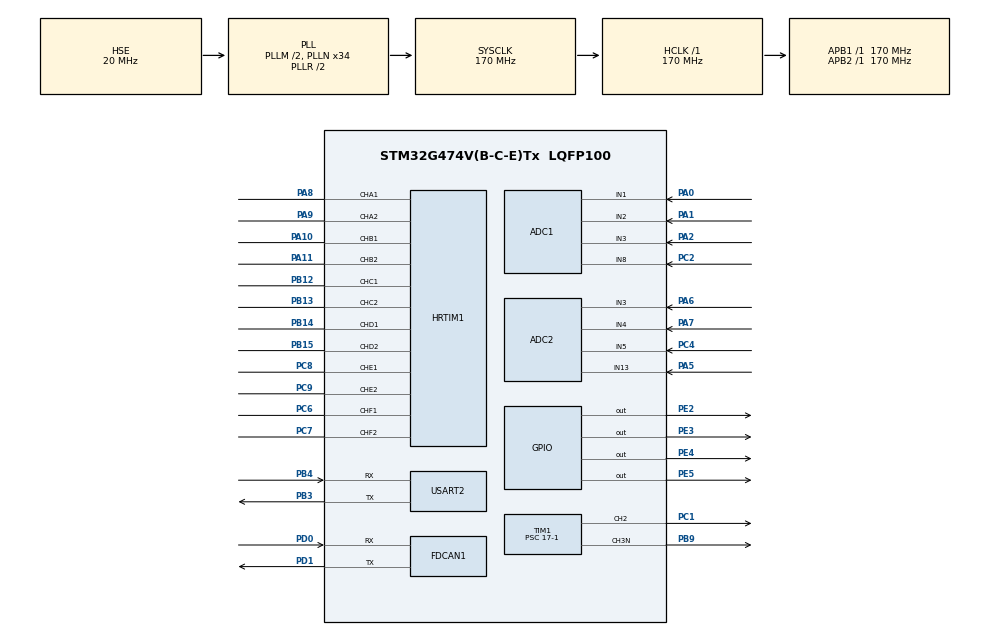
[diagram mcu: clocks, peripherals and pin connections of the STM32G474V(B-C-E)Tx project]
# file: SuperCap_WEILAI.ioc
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ADC1.Channel-22\#ChannelRegularConversion=ADC_CHANNEL_2
ADC1.Channel-23\#ChannelRegularConversion=ADC_CHANNEL_8
ADC1.ClockPrescaler=ADC_CLOCK_ASYNC_DIV8
ADC1.ContinuousConvMode=DISABLE
ADC1.DMAContinuousRequests=ENABLE
ADC1.DiscontinuousConvMode=DISABLE
ADC1.EOCSelection=ADC_EOC_SEQ_CONV
ADC1.EnableInjectedConversion=ENABLE
ADC1.EnableRegularConversion=ENABLE
ADC1.ExternalTrigConv=ADC_EXTERNALTRIG_HRTIM_TRG1
ADC1.ExternalTrigInjecConv=ADC_EXTERNALTRIGINJEC_HRTIM_TRG4
ADC1.GainCompensation=0
ADC1.InjNumberOfConversion=2
ADC1.InjectedChannel-20\#ChannelInjectedConversion=ADC_CHANNEL_1
ADC1.InjectedChannel-21\#ChannelInjectedConversion=ADC_CHANNEL_3
ADC1.InjectedOffsetNumber-20\#ChannelInjectedConversion=ADC_OFFSET_NONE
ADC1.InjectedOffsetNumber-21\#ChannelInjectedConversion=ADC_OFFSET_NONE
ADC1.InjectedRank-20\#ChannelInjectedConversion=1
ADC1.InjectedRank-21\#ChannelInjectedConversion=2
ADC1.InjectedSamplingTime-20\#ChannelInjectedConversion=ADC_SAMPLETIME_6CYCLES_5
ADC1.InjectedSamplingTime-21\#ChannelInjectedConversion=ADC_SAMPLETIME_6CYCLES_5
ADC1.Mode=ADC_MODE_INDEPENDENT
ADC1.NbrOfConversion=2
ADC1.NbrOfConversionFlag=1
ADC1.OffsetNumber-22\#ChannelRegularConversion=ADC_OFFSET_NONE
ADC1.OffsetNumber-23\#ChannelRegularConversion=ADC_OFFSET_NONE
ADC1.Overrun=ADC_OVR_DATA_OVERWRITTEN
ADC1.Rank-22\#ChannelRegularConversion=1
ADC1.Rank-23\#ChannelRegularConversion=2
ADC1.Rank1_Channel=ADC_CHANNEL_1
ADC1.Rank2_Channel=ADC_CHANNEL_3
ADC1.Rank3_Channel=ADC_CHANNEL_1
ADC1.Rank4_Channel=ADC_CHANNEL_1
ADC1.SamplingTime-22\#ChannelRegularConversion=ADC_SAMPLETIME_6CYCLES_5
ADC1.SamplingTime-23\#ChannelRegularConversion=ADC_SAMPLETIME_6CYCLES_5
ADC1.injectedQueueMode=DISABLE
ADC1.master=1
ADC2.Channel-0\#ChannelRegularConversion=ADC_CHANNEL_3
ADC2.Channel-1\#ChannelRegularConversion=ADC_CHANNEL_4
ADC2.Channel-2\#ChannelRegularConversion=ADC_CHANNEL_5
ADC2.Channel-3\#ChannelRegularConversion=ADC_CHANNEL_13
ADC2.ClockPrescaler=ADC_CLOCK_ASYNC_DIV8
ADC2.ContinuousConvMode=DISABLE
ADC2.DMAContinuousRequests=ENABLE
ADC2.ExternalTrigConv=ADC_EXTERNALTRIG_HRTIM_TRG10
ADC2.NbrOfConversion=4
ADC2.NbrOfConversionFlag=1
ADC2.OffsetNumber-0\#ChannelRegularConversion=ADC_OFFSET_NONE
ADC2.OffsetNumber-1\#ChannelRegularConversion=ADC_OFFSET_NONE
ADC2.OffsetNumber-2\#ChannelRegularConversion=ADC_OFFSET_NONE
ADC2.OffsetNumber-3\#ChannelRegularConversion=ADC_OFFSET_NONE
ADC2.Overrun=ADC_OVR_DATA_OVERWRITTEN
ADC2.Rank-0\#ChannelRegularConversion=1
ADC2.Rank-1\#ChannelRegularConversion=2
ADC2.Rank-2\#ChannelRegularConversion=3
ADC2.Rank-3\#ChannelRegularConversion=4
ADC2.SamplingTime-0\#ChannelRegularConversion=ADC_SAMPLETIME_6CYCLES_5
ADC2.SamplingTime-1\#ChannelRegularConversion=ADC_SAMPLETIME_6CYCLES_5
ADC2.SamplingTime-2\#ChannelRegularConversion=ADC_SAMPLETIME_6CYCLES_5
ADC2.SamplingTime-3\#ChannelRegularConversion=ADC_SAMPLETIME_6CYCLES_5
Dma.ADC1.1.Direction=DMA_PERIPH_TO_MEMORY
Dma.ADC1.1.EventEnable=DISABLE
Dma.ADC1.1.Instance=DMA1_Channel1
Dma.ADC1.1.MemDataAlignment=DMA_MDATAALIGN_WORD
Dma.ADC1.1.MemInc=DMA_MINC_ENABLE
Dma.ADC1.1.Mode=DMA_CIRCULAR
Dma.ADC1.1.PeriphDataAlignment=DMA_PDATAALIGN_HALFWORD
Dma.ADC1.1.PeriphInc=DMA_PINC_DISABLE
Dma.ADC1.1.Polarity=HAL_DMAMUX_REQ_GEN_RISING
Dma.ADC1.1.Priority=DMA_PRIORITY_VERY_HIGH
Dma.ADC1.1.RequestNumber=1
Dma.ADC1.1.SignalID=NONE
Dma.ADC1.1.SyncEnable=DISABLE
Dma.ADC1.1.SyncPolarity=HAL_DMAMUX_SYNC_NO_EVENT
Dma.ADC1.1.SyncRequestNumber=1
Dma.ADC1.1.SyncSignalID=NONE
Dma.ADC2.0.Direction=DMA_PERIPH_TO_MEMORY
Dma.ADC2.0.EventEnable=DISABLE
Dma.ADC2.0.Instance=DMA1_Channel2
Dma.ADC2.0.MemDataAlignment=DMA_MDATAALIGN_WORD
Dma.ADC2.0.MemInc=DMA_MINC_ENABLE
Dma.ADC2.0.Mode=DMA_CIRCULAR
Dma.ADC2.0.PeriphDataAlignment=DMA_PDATAALIGN_HALFWORD
Dma.ADC2.0.PeriphInc=DMA_PINC_DISABLE
Dma.ADC2.0.Polarity=HAL_DMAMUX_REQ_GEN_RISING
Dma.ADC2.0.Priority=DMA_PRIORITY_VERY_HIGH
Dma.ADC2.0.RequestNumber=1
Dma.ADC2.0.SignalID=NONE
Dma.ADC2.0.SyncEnable=DISABLE
Dma.ADC2.0.SyncPolarity=HAL_DMAMUX_SYNC_NO_EVENT
Dma.ADC2.0.SyncRequestNumber=1
Dma.ADC2.0.SyncSignalID=NONE
Dma.Request0=ADC2
Dma.Request1=ADC1
FDCAN1.CalculateBaudRateNominal=1000000
FDCAN1.CalculateTimeBitNominal=1000
FDCAN1.CalculateTimeQuantumNominal=100.0
FDCAN1.NominalPrescaler=17
FDCAN1.NominalTimeSeg1=7
FDCAN1.NominalTimeSeg2=2
FDCAN1.StdFiltersNbr=1
HRTIM1.ADCTrigger1_Source1=HRTIM_ADCTRIGGEREVENT13_TIMERF_CMP2
HRTIM1.ADCTrigger4_Source1=HRTIM_ADCTRIGGEREVENT24_TIMERB_CMP2
HRTIM1.ADCTrigger_Id1=HRTIM_ADCTRIGGER_1
HRTIM1.ADCTrigger_Id10=HRTIM_ADCTRIGGER_10
HRTIM1.ADCTrigger_Id2=__NULL
HRTIM1.ADCTrigger_Id3=__NULL
HRTIM1.ADCTrigger_Id4=HRTIM_ADCTRIGGER_4
HRTIM1.ADCTrigger_Id5=__NULL
HRTIM1.ADCTrigger_Id9=__NULL
HRTIM1.BurstMode-Output_TA1TA2=HRTIM_TIMERBURSTMODE_MAINTAINCLOCK
HRTIM1.CompareUnit1-MasterTimer=HRTIM_COMPAREUNIT_1
HRTIM1.CompareUnit1-Output_TA1TA2=HRTIM_COMPAREUNIT_1
HRTIM1.CompareUnit1-Output_TB1TB2=HRTIM_COMPAREUNIT_1
HRTIM1.CompareUnit1-Output_TC1TC2=HRTIM_COMPAREUNIT_1
HRTIM1.CompareUnit1-Output_TD1TD2=HRTIM_COMPAREUNIT_1
HRTIM1.CompareUnit1-Output_TE1TE2=HRTIM_COMPAREUNIT_1
HRTIM1.CompareUnit1-Output_TF1TF2=HRTIM_COMPAREUNIT_1
HRTIM1.CompareUnit2-MasterTimer=HRTIM_COMPAREUNIT_2
HRTIM1.CompareUnit2-Output_TA1TA2=HRTIM_COMPAREUNIT_2
HRTIM1.CompareUnit2-Output_TB1TB2=HRTIM_COMPAREUNIT_2
HRTIM1.CompareUnit2-Output_TC1TC2=HRTIM_COMPAREUNIT_2
HRTIM1.CompareUnit2-Output_TD1TD2=HRTIM_COMPAREUNIT_2
HRTIM1.CompareUnit2-Output_TE1TE2=HRTIM_COMPAREUNIT_2
HRTIM1.CompareUnit2-Output_TF1TF2=HRTIM_COMPAREUNIT_2
HRTIM1.CompareUnit3-Output_TA1TA2=HRTIM_COMPAREUNIT_3
HRTIM1.CompareUnit3-Output_TB1TB2=HRTIM_COMPAREUNIT_3
HRTIM1.CompareUnit3-Output_TC1TC2=HRTIM_COMPAREUNIT_3
HRTIM1.CompareUnit3-Output_TD1TD2=HRTIM_COMPAREUNIT_3
HRTIM1.CompareUnit3-Output_TE1TE2=HRTIM_COMPAREUNIT_3
HRTIM1.CompareUnit3-Output_TF1TF2=HRTIM_COMPAREUNIT_3
HRTIM1.CompareUnit4-Output_TA1TA2=__NULL
HRTIM1.CompareValue1-MasterTimer=8000
HRTIM1.CompareValue1-Output_TA1TA2=0xFFDF
HRTIM1.CompareValue1-Output_TB1TB2=0xFFDF
HRTIM1.CompareValue1-Output_TC1TC2=0xFFDF
HRTIM1.CompareValue1-Output_TD1TD2=0xFFDF
HRTIM1.CompareValue1-Output_TE1TE2=0xFFDF
HRTIM1.CompareValue1-Output_TF1TF2=0xFFDF
HRTIM1.CompareValue2-MasterTimer=16000
HRTIM1.CompareValue2-Output_TA1TA2=12000
HRTIM1.CompareValue2-Output_TB1TB2=12000
HRTIM1.CompareValue2-Output_TC1TC2=12000
HRTIM1.CompareValue2-Output_TD1TD2=12000
HRTIM1.CompareValue2-Output_TE1TE2=12000
HRTIM1.CompareValue2-Output_TF1TF2=12000
HRTIM1.CompareValue3-Output_TE1TE2=0xFFDF
HRTIM1.DeadTimeInsertion-Output_TA1TA2=HRTIM_TIMDEADTIMEINSERTION_ENABLED
HRTIM1.DeadTimeInsertion-Output_TB1TB2=HRTIM_TIMDEADTIMEINSERTION_ENABLED
HRTIM1.DeadTimeInsertion-Output_TC1TC2=HRTIM_TIMDEADTIMEINSERTION_ENABLED
HRTIM1.DeadTimeInsertion-Output_TD1TD2=HRTIM_TIMDEADTIMEINSERTION_ENABLED
HRTIM1.DeadTimeInsertion-Output_TE1TE2=HRTIM_TIMDEADTIMEINSERTION_ENABLED
HRTIM1.DeadTimeInsertion-Output_TF1TF2=HRTIM_TIMDEADTIMEINSERTION_ENABLED
HRTIM1.FallingValue-Output_TA1TA2=55
HRTIM1.FallingValue-Output_TB1TB2=55
HRTIM1.FallingValue-Output_TC1TC2=55
HRTIM1.FallingValue-Output_TD1TD2=55
HRTIM1.FallingValue-Output_TE1TE2=55
HRTIM1.FallingValue-Output_TF1TF2=55
HRTIM1.FaultLevel1-Output_TA1TA2=HRTIM_OUTPUTFAULTLEVEL_INACTIVE
HRTIM1.FaultLevel1-Output_TC1TC2=HRTIM_OUTPUTFAULTLEVEL_INACTIVE
HRTIM1.FaultLevel1-Output_TD1TD2=HRTIM_OUTPUTFAULTLEVEL_INACTIVE
HRTIM1.FaultLevel1-Output_TE1TE2=HRTIM_OUTPUTFAULTLEVEL_INACTIVE
HRTIM1.FaultLevel1-Output_TF1TF2=HRTIM_OUTPUTFAULTLEVEL_INACTIVE
HRTIM1.FaultLevel2-Output_TA1TA2=HRTIM_OUTPUTFAULTLEVEL_INACTIVE
HRTIM1.FaultLevel2-Output_TC1TC2=HRTIM_OUTPUTFAULTLEVEL_INACTIVE
HRTIM1.FaultLevel2-Output_TD1TD2=HRTIM_OUTPUTFAULTLEVEL_INACTIVE
HRTIM1.FaultLevel2-Output_TE1TE2=HRTIM_OUTPUTFAULTLEVEL_INACTIVE
HRTIM1.FaultLevel2-Output_TF1TF2=HRTIM_OUTPUTFAULTLEVEL_INACTIVE
HRTIM1.FaultLock-Output_TA1TA2=HRTIM_TIMFAULTLOCK_READWRITE
HRTIM1.InterruptRequests1_Master=HRTIM_MASTER_IT_MREP
HRTIM1.NumberADCTriggerSource1=1
HRTIM1.NumberADCTriggerSource4=1
HRTIM1.NumberFaultEnable-Output_TA1TA2=0
HRTIM1.NumberInterruptRequests_Master-MasterTimer=1
HRTIM1.NumberResetSource1-Output_TA1TA2=1
HRTIM1.NumberResetSource1-Output_TB1TB2=1
HRTIM1.NumberResetSource1-Output_TC1TC2=1
HRTIM1.NumberResetSource1-Output_TD1TD2=1
HRTIM1.NumberResetSource1-Output_TE1TE2=1
HRTIM1.NumberResetSource1-Output_TF1TF2=1
HRTIM1.NumberResetSource2_TB=0
HRTIM1.NumberResetTrigger-Output_TA1TA2=1
HRTIM1.NumberResetTrigger-Output_TB1TB2=1
HRTIM1.NumberResetTrigger-Output_TC1TC2=1
HRTIM1.NumberResetTrigger-Output_TD1TD2=1
HRTIM1.NumberResetTrigger-Output_TE1TE2=1
HRTIM1.NumberResetTrigger-Output_TF1TF2=1
HRTIM1.NumberSetSource1-Output_TA1TA2=1
HRTIM1.NumberSetSource1-Output_TB1TB2=1
HRTIM1.NumberSetSource1-Output_TC1TC2=1
HRTIM1.NumberSetSource1-Output_TD1TD2=1
HRTIM1.NumberSetSource1-Output_TE1TE2=1
HRTIM1.NumberSetSource1-Output_TF1TF2=1
HRTIM1.NumberSetSource2_TA=0
HRTIM1.NumberUpdateTrigger-Output_TA1TA2=0
HRTIM1.NumberUpdateTrigger-Output_TF1TF2=0
HRTIM1.ORingUpdateSource_ADCTrigger1=HRTIM_ADCTRIGGERUPDATE_TIMER_F
HRTIM1.ORingUpdateSource_ADCTrigger10=HRTIM_ADCTRIGGERUPDATE_TIMER_C
HRTIM1.ORingUpdateSource_ADCTrigger4=HRTIM_ADCTRIGGERUPDATE_TIMER_B
HRTIM1.Periode_MASTER=24000
HRTIM1.Periode_TA=24000
HRTIM1.Periode_TB=24000
HRTIM1.Periode_TC=24000
HRTIM1.Periode_TD=24000
HRTIM1.Periode_TE=24000
HRTIM1.Periode_TF=24000
HRTIM1.PreloadEnable-MasterTimer=HRTIM_PRELOAD_ENABLED
HRTIM1.PreloadEnable-Output_TA1TA2=HRTIM_PRELOAD_ENABLED
HRTIM1.PreloadEnable-Output_TB1TB2=HRTIM_PRELOAD_ENABLED
HRTIM1.PreloadEnable-Output_TC1TC2=HRTIM_PRELOAD_ENABLED
HRTIM1.PreloadEnable-Output_TD1TD2=HRTIM_PRELOAD_ENABLED
HRTIM1.PreloadEnable-Output_TE1TE2=HRTIM_PRELOAD_ENABLED
HRTIM1.PreloadEnable-Output_TF1TF2=HRTIM_PRELOAD_ENABLED
HRTIM1.PrescalerDead-Output_TA1TA2=HRTIM_TIMDEADTIME_PRESCALERRATIO_DIV8
HRTIM1.PrescalerDead-Output_TB1TB2=HRTIM_TIMDEADTIME_PRESCALERRATIO_DIV8
HRTIM1.PrescalerDead-Output_TC1TC2=HRTIM_TIMDEADTIME_PRESCALERRATIO_DIV8
HRTIM1.PrescalerDead-Output_TD1TD2=HRTIM_TIMDEADTIME_PRESCALERRATIO_DIV8
HRTIM1.PrescalerDead-Output_TE1TE2=HRTIM_TIMDEADTIME_PRESCALERRATIO_DIV8
HRTIM1.PrescalerDead-Output_TF1TF2=HRTIM_TIMDEADTIME_PRESCALERRATIO_DIV8
HRTIM1.PrescalerRatio_MASTER=HRTIM_PRESCALERRATIO_MUL32
HRTIM1.RepetitionCounter-MasterTimer=8-1
HRTIM1.RepetitionUpdate-MasterTimer=HRTIM_UPDATEONREPETITION_ENABLED
HRTIM1.RepetitionUpdate-Output_TA1TA2=HRTIM_UPDATEONREPETITION_ENABLED
HRTIM1.RepetitionUpdate-Output_TB1TB2=HRTIM_UPDATEONREPETITION_ENABLED
HRTIM1.RepetitionUpdate-Output_TC1TC2=HRTIM_UPDATEONREPETITION_ENABLED
HRTIM1.RepetitionUpdate-Output_TD1TD2=HRTIM_UPDATEONREPETITION_ENABLED
HRTIM1.RepetitionUpdate-Output_TE1TE2=HRTIM_UPDATEONREPETITION_ENABLED
HRTIM1.RepetitionUpdate-Output_TF1TF2=HRTIM_UPDATEONREPETITION_ENABLED
HRTIM1.ResetOutput1_Source1-Output_TA1TA2=HRTIM_OUTPUTRESET_TIMCMP3
HRTIM1.ResetOutput1_Source1-Output_TB1TB2=HRTIM_OUTPUTRESET_TIMCMP3
HRTIM1.ResetOutput1_Source1-Output_TC1TC2=HRTIM_OUTPUTRESET_TIMCMP3
HRTIM1.ResetOutput1_Source1-Output_TD1TD2=HRTIM_OUTPUTRESET_TIMCMP3
HRTIM1.ResetOutput1_Source1-Output_TE1TE2=HRTIM_OUTPUTRESET_TIMCMP3
HRTIM1.ResetOutput1_Source1-Output_TF1TF2=HRTIM_OUTPUTRESET_TIMCMP3
HRTIM1.ResetTrigger1-Output_TA1TA2=HRTIM_TIMRESETTRIGGER_MASTER_PER
HRTIM1.ResetTrigger1-Output_TB1TB2=HRTIM_TIMRESETTRIGGER_MASTER_PER
HRTIM1.ResetTrigger1-Output_TC1TC2=HRTIM_TIMRESETTRIGGER_MASTER_CMP2
HRTIM1.ResetTrigger1-Output_TD1TD2=HRTIM_TIMRESETTRIGGER_MASTER_CMP2
HRTIM1.ResetTrigger1-Output_TE1TE2=HRTIM_TIMRESETTRIGGER_MASTER_CMP1
HRTIM1.ResetTrigger1-Output_TF1TF2=HRTIM_TIMRESETTRIGGER_MASTER_CMP1
HRTIM1.ResetUpdate-Output_TA1TA2=HRTIM_TIMUPDATEONRESET_ENABLED
HRTIM1.ResetUpdate-Output_TB1TB2=HRTIM_TIMUPDATEONRESET_ENABLED
HRTIM1.ResetUpdate-Output_TC1TC2=HRTIM_TIMUPDATEONRESET_ENABLED
HRTIM1.ResetUpdate-Output_TD1TD2=HRTIM_TIMUPDATEONRESET_ENABLED
HRTIM1.ResetUpdate-Output_TE1TE2=HRTIM_TIMUPDATEONRESET_ENABLED
HRTIM1.ResetUpdate-Output_TF1TF2=HRTIM_TIMUPDATEONRESET_ENABLED
HRTIM1.RisingValue-Output_TA1TA2=55
HRTIM1.RisingValue-Output_TB1TB2=55
HRTIM1.RisingValue-Output_TC1TC2=55
HRTIM1.RisingValue-Output_TD1TD2=55
HRTIM1.RisingValue-Output_TE1TE2=55
HRTIM1.RisingValue-Output_TF1TF2=55
HRTIM1.SetOutput1_Source1-Output_TA1TA2=HRTIM_OUTPUTSET_TIMCMP1
HRTIM1.SetOutput1_Source1-Output_TB1TB2=HRTIM_OUTPUTSET_TIMCMP1
HRTIM1.SetOutput1_Source1-Output_TC1TC2=HRTIM_OUTPUTSET_TIMCMP1
HRTIM1.SetOutput1_Source1-Output_TD1TD2=HRTIM_OUTPUTSET_TIMCMP1
HRTIM1.SetOutput1_Source1-Output_TE1TE2=HRTIM_OUTPUTSET_TIMCMP1
HRTIM1.SetOutput1_Source1-Output_TF1TF2=HRTIM_OUTPUTSET_TIMCMP1
HRTIM1.Source_ADCTrigger10=HRTIM_ADCTRIGGEREVENT6810_TIMERC_CMP2
HRTIM1.SwapC=__NULL
HRTIM1.UpDownMode-Output_TA1TA2=HRTIM_TIMERUPDOWNMODE_UP
HRTIM1.UpDownMode-Output_TB1TB2=HRTIM_TIMERUPDOWNMODE_UP
HRTIM1.UpDownMode-Output_TC1TC2=HRTIM_TIMERUPDOWNMODE_UP
HRTIM1.UpDownMode-Output_TE1TE2=HRTIM_TIMERUPDOWNMODE_UP
HRTIM1.UpDownMode-Output_TF1TF2=HRTIM_TIMERUPDOWNMODE_UP
IWDG.Prescaler=IWDG_PRESCALER_64
IWDG.Reload=100
Mcu.Family=STM32G4
Mcu.Name=STM32G474V(B-C-E)Tx
Mcu.Package=LQFP100
NVIC.ADC1_2_IRQn=true\:0\:0\:false\:false\:false\:true\:true\:true
NVIC.FDCAN1_IT0_IRQn=true\:0\:0\:false\:false\:false\:true\:true\:true
NVIC.HRTIM1_Master_IRQn=true\:0\:0\:false\:false\:false\:true\:true\:true
NVIC.PriorityGroup=NVIC_PRIORITYGROUP_4
NVIC.TIM2_IRQn=true\:0\:0\:false\:false\:false\:true\:true\:true
PA0.Mode=IN1-Single-Ended
PA0.Signal=ADC1_IN1
PA1.Mode=IN2-Single-Ended
PA1.Signal=ADC1_IN2
PA10.Mode=Output_TB1TB2
PA10.Signal=HRTIM1_CHB1
PA11.Mode=Output_TB1TB2
PA11.Signal=HRTIM1_CHB2
PA13.Mode=Serial_Wire
PA13.Signal=SYS_JTMS-SWDIO
PA14.Mode=Serial_Wire
PA14.Signal=SYS_JTCK-SWCLK
PA2.Mode=IN3-Single-Ended
PA2.Signal=ADC1_IN3
PA5.Mode=IN13-Single-Ended
PA5.Signal=ADC2_IN13
PA6.Mode=IN3-Single-Ended
PA6.Signal=ADC2_IN3
PA7.Mode=IN4-Single-Ended
PA7.Signal=ADC2_IN4
PA8.Mode=Output_TA1TA2
PA8.Signal=HRTIM1_CHA1
PA9.Mode=Output_TA1TA2
PA9.Signal=HRTIM1_CHA2
PB12.Mode=Output_TC1TC2
PB12.Signal=HRTIM1_CHC1
PB13.Mode=Output_TC1TC2
PB13.Signal=HRTIM1_CHC2
PB14.Mode=Output_TD1TD2
PB14.Signal=HRTIM1_CHD1
PB15.Mode=Output_TD1TD2
PB15.Signal=HRTIM1_CHD2
PB3.Mode=Asynchronous
PB3.Signal=USART2_TX
PB4.Mode=Asynchronous
PB4.Signal=USART2_RX
PB9.Mode=PWM Generation3 CH3N
PB9.Signal=TIM1_CH3N
PC1.GPIO_PuPd=GPIO_PULLDOWN
PC1.Signal=S_TIM1_CH2
PC2.Mode=IN8-Single-Ended
PC2.Signal=ADC1_IN8
PC4.Mode=IN5-Single-Ended
PC4.Signal=ADC2_IN5
PC6.Mode=Output_TF1TF2
PC6.Signal=HRTIM1_CHF1
PC7.Mode=Output_TF1TF2
PC7.Signal=HRTIM1_CHF2
PC8.Mode=Output_TE1TE2
PC8.Signal=HRTIM1_CHE1
PC9.Mode=Output_TE1TE2
PC9.Signal=HRTIM1_CHE2
PD0.Mode=FDCAN_Activate
PD0.Signal=FDCAN1_RX
PD1.Mode=FDCAN_Activate
PD1.Signal=FDCAN1_TX
PE2.GPIO_ModeDefaultOutputPP=GPIO_MODE_OUTPUT_PP
PE2.GPIO_PuPd=GPIO_PULLDOWN
PE2.PinState=GPIO_PIN_RESET
PE2.Signal=GPIO_Output
PE3.GPIO_ModeDefaultOutputPP=GPIO_MODE_OUTPUT_PP
PE3.GPIO_PuPd=GPIO_PULLDOWN
PE3.PinState=GPIO_PIN_RESET
PE3.Signal=GPIO_Output
PE4.GPIO_PuPd=GPIO_PULLDOWN
PE4.PinState=GPIO_PIN_RESET
PE4.Signal=GPIO_Output
PE5.GPIO_PuPd=GPIO_PULLDOWN
PE5.PinState=GPIO_PIN_RESET
PE5.Signal=GPIO_Output
PF0-OSC_IN.Mode=HSE-External-Oscillator
PF0-OSC_IN.Signal=RCC_OSC_IN
PF1-OSC_OUT.Mode=HSE-External-Oscillator
PF1-OSC_OUT.Signal=RCC_OSC_OUT
ProjectManager.HeapSize=0x200
ProjectManager.StackSize=0x400
ProjectManager.TargetToolchain=CMake
RCC.ADC12Freq_Value=170000000
RCC.ADC345Freq_Value=170000000
RCC.AHBFreq_Value=170000000
RCC.APB1Freq_Value=170000000
RCC.APB1TimFreq_Value=170000000
RCC.APB2Freq_Value=170000000
RCC.APB2TimFreq_Value=170000000
RCC.CortexFreq_Value=170000000
RCC.EXTERNAL_CLOCK_VALUE=12288000
RCC.HCLKFreq_Value=170000000
RCC.HSE_VALUE=20000000
RCC.HSI48_VALUE=48000000
RCC.HSI_VALUE=16000000
RCC.LSE_VALUE=32768
RCC.PLLM=RCC_PLLM_DIV2
RCC.PLLN=34
RCC.PLLSourceVirtual=RCC_PLLSOURCE_HSE
RCC.SYSCLKFreq_VALUE=170000000
RCC.SYSCLKSource=RCC_SYSCLKSOURCE_PLLCLK
RCC.USBFreq_Value=170000000
RCC.VCOOutputFreq_Value=340000000
SH.S_TIM1_CH2.0=TIM1_CH2,PWM Generation2 CH2
SYS.VoltageScaling=SYSCFG_VREFBUF_VOLTAGE_SCALE2
TIM1.Channel-PWM\ Generation2\ CH2=TIM_CHANNEL_2
TIM1.Channel-PWM\ Generation3\ CH3=TIM_CHANNEL_3
TIM1.Channel-PWM\ Generation3\ CH3N=TIM_CHANNEL_3
TIM1.PeriodNoDither=0
TIM1.Prescaler=17-1
TIM2.AutoReloadPreload=TIM_AUTORELOAD_PRELOAD_ENABLE
TIM2.PeriodNoDither=10000-1
TIM2.Prescaler=17-1
USART2.VirtualMode-Asynchronous=VM_ASYNC
VP_HRTIM1_VS_hrtimMasterTimerNoOutput.Mode=MasterTimer
VP_IWDG_VS_IWDG.Mode=IWDG_Activate
VP_SYS_VS_DBSignals.Mode=DisableDeadBatterySignals
VP_TIM1_VS_ClockSourceINT.Mode=Internal
VP_TIM2_VS_ClockSourceINT.Mode=Internal
VREF+.Mode=InternalMode
VREF+.Signal=VREFBUF_OUT
board=custom

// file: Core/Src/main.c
/* USER CODE BEGIN Header */
/**
 ******************************************************************************
 * @file           : main.c
 * @brief          : Main program body
 ******************************************************************************
 * @attention
 *
 * Copyright (c) 2026 STMicroelectronics.
 * All rights reserved.
 *
 * This software is licensed under terms that can be found in the LICENSE file
 * in the root directory of this software component.
 * If no LICENSE file comes with this software, it is provided AS-IS.
 *
 ******************************************************************************
 */
/* USER CODE END Header */
#include "main.h"
#include "adc.h"
#include "dma.h"
#include "fdcan.h"
#include "hrtim.h"
#include "tim.h"
#include "usart.h"
#include "gpio.h"

/* USER CODE BEGIN Includes */
#include "SuperCap.h"
#include "dev_led.h"

/* USER CODE END Includes */

void SystemClock_Config(void);

int main(void)
{

  /* MCU Configuration--------------------------------------------------------*/

  /* Reset of all peripherals, Initializes the Flash interface and the Systick. */
  HAL_Init();

  /* Configure the system clock */
  SystemClock_Config();

  /* Initialize all configured peripherals */
  MX_GPIO_Init();
  MX_DMA_Init();
  MX_ADC1_Init();
  MX_ADC2_Init();
  MX_FDCAN1_Init();
  MX_HRTIM1_Init();
  MX_USART2_UART_Init();
  MX_TIM1_Init();
  MX_TIM2_Init();
  /* USER CODE BEGIN 2 */
    SuperCap_Start();
    Device_LED_SetSysState(DEV_LED_SYS_NORMAL);
  /* USER CODE END 2 */

  /* Infinite loop */
  /* USER CODE BEGIN WHILE */
    while (1)
    {
        Device_LED_Task(HAL_GetTick());
    /* USER CODE END WHILE */

    }
}

void SystemClock_Config(void)
{
  RCC_OscInitTypeDef RCC_OscInitStruct = {0};
  RCC_ClkInitTypeDef RCC_ClkInitStruct = {0};

  /** Configure the main internal regulator output voltage
  */
  HAL_PWREx_ControlVoltageScaling(PWR_REGULATOR_VOLTAGE_SCALE1_BOOST);

  /** Initializes the RCC Oscillators according to the specified parameters
  * in the RCC_OscInitTypeDef structure.
  */
  RCC_OscInitStruct.OscillatorType = RCC_OSCILLATORTYPE_HSE;
  RCC_OscInitStruct.HSEState = RCC_HSE_ON;
  RCC_OscInitStruct.PLL.PLLState = RCC_PLL_ON;
  RCC_OscInitStruct.PLL.PLLSource = RCC_PLLSOURCE_HSE;
  RCC_OscInitStruct.PLL.PLLM = RCC_PLLM_DIV2;
  RCC_OscInitStruct.PLL.PLLN = 34;
  RCC_OscInitStruct.PLL.PLLP = RCC_PLLP_DIV2;
  RCC_OscInitStruct.PLL.PLLQ = RCC_PLLQ_DIV2;
  RCC_OscInitStruct.PLL.PLLR = RCC_PLLR_DIV2;
  if (HAL_RCC_OscConfig(&RCC_OscInitStruct) != HAL_OK)
  {
    Error_Handler();
  }

  /** Initializes the CPU, AHB and APB buses clocks
  */
  RCC_ClkInitStruct.ClockType = RCC_CLOCKTYPE_HCLK|RCC_CLOCKTYPE_SYSCLK
                              |RCC_CLOCKTYPE_PCLK1|RCC_CLOCKTYPE_PCLK2;
  RCC_ClkInitStruct.SYSCLKSource = RCC_SYSCLKSOURCE_PLLCLK;
  RCC_ClkInitStruct.AHBCLKDivider = RCC_SYSCLK_DIV1;
  RCC_ClkInitStruct.APB1CLKDivider = RCC_HCLK_DIV1;
  RCC_ClkInitStruct.APB2CLKDivider = RCC_HCLK_DIV1;

  if (HAL_RCC_ClockConfig(&RCC_ClkInitStruct, FLASH_LATENCY_4) != HAL_OK)
  {
    Error_Handler();
  }
}

void Error_Handler(void)
{
    __disable_irq();
    while (1)
    {
    }
}
